VERSION ""

NS_ :

BS_:

BU_:

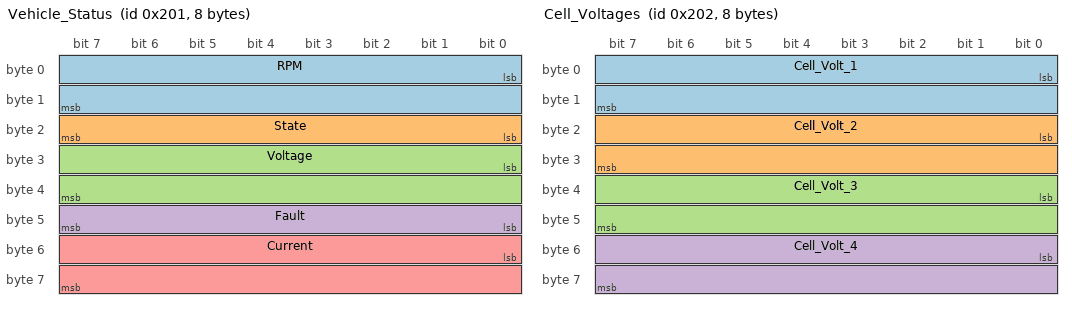
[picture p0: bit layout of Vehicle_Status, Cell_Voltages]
BO_ 513 Vehicle_Status: 8 Vector__XXX
 SG_ RPM : 0|16@1+ (1,0) [0|65535] "rpm" Vector__XXX
 SG_ State : 16|8@1+ (1,0) [0|6] "" Vector__XXX
 SG_ Voltage : 24|16@1+ (0.001,0) [0|65.535] "V" Vector__XXX
 SG_ Fault : 40|8@1+ (1,0) [0|255] "" Vector__XXX
 SG_ Current : 48|16@1- (0.001,0) [-32.768|32.767] "A" Vector__XXX

BO_ 514 Cell_Voltages: 8 Vector__XXX
 SG_ Cell_Volt_1 : 0|16@1+ (0.001,0) [0|65.535] "V" Vector__XXX
 SG_ Cell_Volt_2 : 16|16@1+ (0.001,0) [0|65.535] "V" Vector__XXX
 SG_ Cell_Volt_3 : 32|16@1+ (0.001,0) [0|65.535] "V" Vector__XXX
 SG_ Cell_Volt_4 : 48|16@1+ (0.001,0) [0|65.535] "V" Vector__XXX

CM_ BO_ 513 "Contains status info";
CM_ SG_ 513 RPM "Motor shaft rotation per miniute";
CM_ SG_ 513 State "State of the Vehicle";
CM_ SG_ 513 Voltage "Battery voltage";
CM_ SG_ 513 Fault "Fault code";
CM_ SG_ 513 Current "Battery current";
CM_ BO_ 514 "Contains voltages of each cell";
CM_ SG_ 514 Cell_Volt_1 "Voltage of Cell 1";
CM_ SG_ 514 Cell_Volt_2 "Voltage of Cell 2
";
CM_ SG_ 514 Cell_Volt_3 "Voltage of Cell 3";
CM_ SG_ 514 Cell_Volt_4 "Voltage of Cell 4";
BA_DEF_  "BusType" STRING ;
BA_DEF_DEF_  "BusType" "CAN";
VAL_ 513 State 0 "SLEEP" 1 "ACTIVE" 2 "FAULT" 3 "WARNING" 4 "DIAGNOSTIC" 5 "CHARGING" ;
